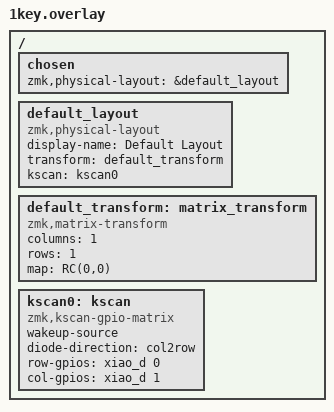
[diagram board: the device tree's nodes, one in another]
#include <dt-bindings/zmk/matrix_transform.h>

/ {
    chosen {
        // 最新仕様：kscanとtransformを内包したphysical-layoutを直接指定する
        zmk,physical-layout = &default_layout;
    };

    // 新設：最新のZMKコアが要求する物理レイアウト定義
    default_layout: default_layout {
        compatible = "zmk,physical-layout";
        display-name = "Default Layout";
        transform = <&default_transform>;
        kscan = <&kscan0>;
    };

    default_transform: matrix_transform {
        compatible = "zmk,matrix-transform";
        columns = <1>;
        rows = <1>;
        map = <
            RC(0,0)
        >;
    };

    kscan0: kscan {
        compatible = "zmk,kscan-gpio-matrix";
        wakeup-source;
        diode-direction = "col2row";
        
        row-gpios = <&xiao_d 0 (GPIO_ACTIVE_HIGH | GPIO_PULL_DOWN)>;
        col-gpios = <&xiao_d 1 GPIO_ACTIVE_HIGH>;
    };
};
